AUTOSAR XML (schema 4-0-3)
standard types defined: Boolean, UInt16
package /AUTOSAR_Platform/DataConstrs
  range DC_UInt16: raw 0..65535
package /PATAC/MSM/ComponentTypes
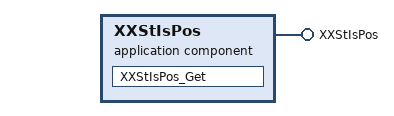
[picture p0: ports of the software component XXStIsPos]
  application sw component type XXStIsPos
    provide port XXStIsPos: server-com-spec{operation=Get, queue-length=1}, provided-interface=XXStIsPos
    behavior XXStIsPos_InternalBehavior
      operation invoked event OIT_XXStIsPos_Get_XXStIsPos_Get: start-on-event=XXStIsPos_Get, operation=XXStIsPos.Get
      runnable XXStIsPos_Get
  swc implementation XXStIsPos_Implementation: behavior=XXStIsPos_InternalBehavior
    code-descriptors:
      code Default: artifact-descriptors=autosar-engineering-object={short-label=Default, category=SWSRC}
package /PATAC/MSM/ModeAdjust/DataType
  impl type TrgtPosCalibArray: category=ARRAY, sw-calibration-access=READ-ONLY, type-emitter=RTE  # 0:pos 1:max 2:min
    element Element: array-size=3, array-size-semantics=FIXED-SIZE, implementation-data-type=UInt16, invalid-value=0
package /PATAC/MSM/ModeAdjust/PortInterface
  client server interface XXStIsPos
    operation Get
      8 x arg, all with server-argument-impl-policy=USE-ARGUMENT-TYPE:
        PosV: type=Boolean, direction=IN
        Pos: type=UInt16, direction=IN
        CalibArray: type=TrgtPosCalibArray, direction=IN
        Delta: type=UInt16, direction=IN
        Tolr: type=UInt16, direction=IN
        IsPos: type=Boolean, direction=OUT
        IsPosZone: type=Boolean, direction=OUT
        IsPosAlready: type=Boolean, direction=OUT
